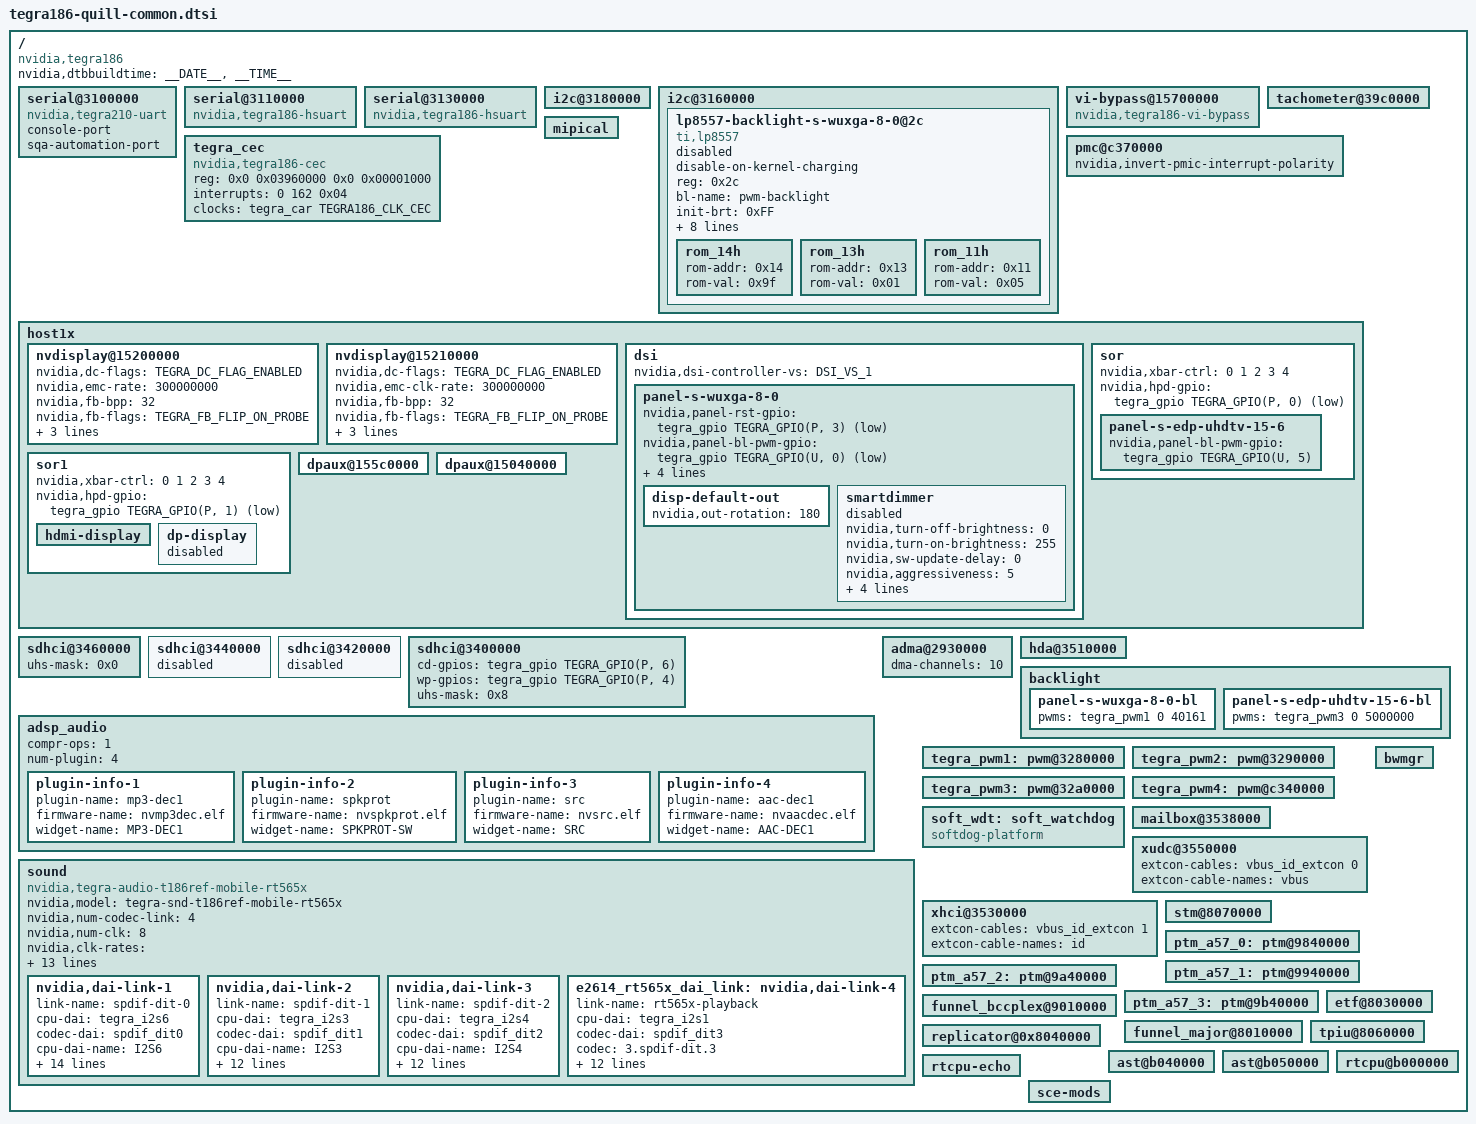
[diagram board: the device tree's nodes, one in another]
/*
 * tegra186-quill-common.dtsi: Quill common dtsi.
 *
 * Copyright (c) 2015-2016, NVIDIA CORPORATION.  All rights reserved.
 *
 * This program is free software; you can redistribute it and/or modify
 * it under the terms of the GNU General Public License as published by
 * the Free Software Foundation; version 2 of the License.
 *
 * This program is distributed in the hope that it will be useful, but WITHOUT
 * ANY WARRANTY; without even the implied warranty of MERCHANTABILITY or
 * FITNESS FOR A PARTICULAR PURPOSE.  See the GNU General Public License for
 * more details.
 */

#include <dt-bindings/types.h>
#include <dt-bindings/gpio/tegra-gpio.h>
/dts-v1/;

/memreserve/ 0x80000000 0x00010000;

#include "tegra186-soc/tegra186-soc-cvm.dtsi"
#include "tegra186-platforms-simple-bus.dtsi"
#include "panel-s-wuxga-8-0.dtsi"
#include "tegra186-platforms/tegra186-quill-eqos.dtsi"
#include "tegra186-hdmi.dtsi"
#include "tegra186-dp.dtsi"
#include "panel-s-edp-uhdtv-15-6.dtsi"
#include "tegra186-quill-pwm-fan.dtsi"
#include "tegra186-quill-thermal-fan-est.dtsi"

/ {
        compatible = "nvidia,tegra186";

        nvidia,dtbbuildtime = __DATE__, __TIME__;
        #address-cells = <2>;
        #size-cells = <2>;

	serial@3100000 {
		compatible = "nvidia,tegra210-uart", "nvidia,tegra186-hsuart";
		console-port;
		sqa-automation-port;
		status = "okay";
	};

	serial@3110000 {
		compatible = "nvidia,tegra186-hsuart";
		status = "okay";
	};

	serial@3130000 {
		compatible = "nvidia,tegra186-hsuart";
		dma-names = "tx";
		status = "okay";
	};

	i2c@3180000 {
		status = "okay";
	};

	i2c@3160000 {
		status = "okay";
		lp8557-backlight-s-wuxga-8-0@2c {
			status = "disabled";
			disable-on-kernel-charging;
			compatible = "ti,lp8557";
			reg = <0x2c>;

			bl-name = "pwm-backlight"; /* Match liblights naming expectations */
			init-brt = /bits/ 8 <0xFF>; /* Max brightness */
			dev-ctrl = /bits/ 8 <0x80>; /* PWM, enable standby mode */
			pwm-period = <40161>;

			pwm-names = "lp8557";
			pwms = <&tegra_pwm1 0 40161>;

			bl-measured = < 0 1 2 3 4 5 5 6
					7 8 9 10 11 11 12 13
					14 15 15 16 17 18 19 20
					21 22 22 23 24 25 26 27
					28 29 30 31 31 32 33 34
					35 36 37 37 38 39 40 41
					41 42 43 44 45 46 47 48
					48 49 50 51 52 53 54 54
					55 56 57 58 58 59 60 61
					62 63 64 65 66 67 68 69
					70 71 72 73 74 75 75 76
					77 78 79 80 81 82 83 84
					85 86 87 88 89 90 91 92
					93 94 94 95 96 97 98 99
					100 101 102 104 105 106 107 108
					109 110 111 112 113 114 115 116
					117 118 119 120 121 122 123 125
					126 127 128 129 130 131 132 133
					134 135 136 137 138 139 140 141
					142 143 144 146 147 148 149 150
					151 152 153 154 155 156 157 158
					159 160 161 162 163 164 165 167
					168 169 170 171 172 173 174 175
					176 178 179 180 181 182 183 184
					185 186 187 188 189 190 191 192
					193 194 195 196 197 199 200 201
					202 203 204 205 206 207 208 210
					211 212 213 214 215 216 217 219
					220 221 222 223 225 226 227 228
					229 230 231 233 234 235 236 237
					238 239 240 241 242 244 245 246
					247 248 249 250 251 253 254 255 >;

			bl-curve = < 0 1 1 2 2 3 3 4
					4 5 5 6 7 7 8 8
					9 9 10 10 11 11 12 12
					13 14 14 15 15 16 16 17
					17 18 18 19 20 20 21 21
					22 22 23 23 24 24 25 25
					26 27 27 28 28 29 29 30
					30 31 31 32 33 33 34 34
					35 35 36 36 37 37 38 38
					39 40 40 41 41 42 42 43
					43 44 44 45 46 46 47 47
					48 48 49 49 50 50 51 52
					52 53 53 54 54 55 55 56
					56 57 57 58 59 59 60 60
					61 61 62 62 63 63 64 65
					65 66 66 67 67 68 68 69
					69 70 70 71 72 72 73 73
					74 74 75 75 76 76 77 78
					78 79 79 80 80 81 81 82
					82 83 83 84 85 85 86 86
					87 87 88 88 89 89 90 92
					94 96 97 99 101 103 105 107
					109 110 112 114 116 118 120 122
					123 125 127 129 131 133 134 136
					138 140 142 144 146 147 149 151
					153 155 157 159 160 162 164 166
					168 170 172 173 175 177 179 181
					183 185 186 188 190 192 194 196
					198 199 201 203 205 207 209 211
					212 214 216 218 220 222 223 225
					227 229 231 233 235 236 238 240
					242 244 246 248 249 251 253 255 >;

			/* 5 LED string */
			rom_14h {
				rom-addr = /bits/ 8 <0x14>;
				rom-val = /bits/ 8 <0x9f>;
			};

			/*Boost freq 1MHZ*/
			rom_13h {
				rom-addr = /bits/ 8 <0x13>;
				rom-val = /bits/ 8 <0x01>;
			};

			/*20mA max */
			rom_11h {
				rom-addr = /bits/ 8 <0x11>;
				rom-val = /bits/ 8 <0x05>;
			};
		};
	};

	vi-bypass@15700000{
		compatible = "nvidia,tegra186-vi-bypass";
		status = "okay";
	};

	tachometer@39c0000 {
		status = "okay";
	};

	tegra_cec {
		status = "okay";
		compatible = "nvidia,tegra186-cec";
		reg = <0x0 0x03960000 0x0 0x00001000>;
		interrupts = <0 162 0x04>;
		clocks = <&tegra_car TEGRA186_CLK_CEC>;
		clock-names = "cec";
	};

	pmc@c370000 {
		nvidia,invert-pmic-interrupt-polarity;
	};

        mipical {
                status = "okay";
        };

	host1x {
		nvdisplay@15200000 {
                        status = "okay";
                        nvidia,dc-flags = <TEGRA_DC_FLAG_ENABLED>;
                        nvidia,emc-rate = <300000000>;
                        nvidia,fb-bpp = <32>;
                        nvidia,fb-flags = <TEGRA_FB_FLIP_ON_PROBE>;
			nvidia,fb-win = <0>;
			nvidia,dc-ctrlnum = <0>;
			nvidia,dc-or-node = "/host1x/dsi";
                };

		nvdisplay@15210000 {
			status = "okay";
			nvidia,dc-flags = <TEGRA_DC_FLAG_ENABLED>;
			nvidia,emc-clk-rate = <300000000>;
			nvidia,fb-bpp = <32>; /* bits per pixel */
			nvidia,fb-flags = <TEGRA_FB_FLIP_ON_PROBE>;
			nvidia,fb-win = <3>;
			nvidia,dc-ctrlnum = <1>;
			nvidia,dc-or-node = "/host1x/sor1";
		};

		dsi {	/* dsi@15300000 */
			nvidia,dsi-controller-vs = <DSI_VS_1>;
			status = "okay";
			panel-s-wuxga-8-0 {
				status = "okay";
				nvidia,panel-rst-gpio = <&tegra_gpio TEGRA_GPIO(P, 3) 1>; /* PP3 */
				nvidia,panel-bl-pwm-gpio = <&tegra_gpio TEGRA_GPIO(U, 0) 1>; /* PU0 */
				nvidia,panel-bl-en-gpio = <&tegra_gpio TEGRA_GPIO(U, 3) 1>; /* PU3 */
				nvidia,panel-en-gpio = <&gpio_i2c_0_77 4 1>; /* tca9539 0x77 Pin 4 */
				nvidia,en-vmm-vpp-with-i2c-config;
				disp-default-out {
					nvidia,out-rotation = <180>;
				};
				smartdimmer {
					status = "disabled";
					nvidia,turn-off-brightness = <0>;
					nvidia,turn-on-brightness = <255>;
					nvidia,sw-update-delay = <0>;
					nvidia,aggressiveness = <5>;
					nvidia,phase-in-settings = <0>;
					nvidia,phase-in-adjustments = <0>;
					nvidia,sd-window-enable = <0>;
					nvidia,bl-device-name = "pwm-backlight";
				};
			};
		};

		sor{
			status = "okay";
			nvidia,xbar-ctrl = <0 1 2 3 4>;
			nvidia,hpd-gpio = <&tegra_gpio TEGRA_GPIO(P, 0) GPIO_ACTIVE_LOW>;
			panel-s-edp-uhdtv-15-6 {
				nvidia,panel-bl-pwm-gpio = <&tegra_gpio TEGRA_GPIO(U, 5) 0>;
			};
		};
		sor1 {
			status = "okay";
			nvidia,xbar-ctrl = <0 1 2 3 4>;
			nvidia,hpd-gpio = <&tegra_gpio TEGRA_GPIO(P, 1) GPIO_ACTIVE_LOW>;
			hdmi-display {
				status = "okay";
			};

			dp-display {
				status = "disabled";
			};
		};
		dpaux@155c0000 {
			status = "okay";
		};
		dpaux@15040000 {
			status = "okay";
		};
	};

	sdhci@3460000 {
		uhs-mask = <0x0>; /*enable HS400 mode*/
		status = "okay";
	};

	sdhci@3440000 {
		status = "disabled";
	};

	sdhci@3420000 {
		status = "disabled";
	};

	sdhci@3400000 {
		cd-gpios = <&tegra_gpio TEGRA_GPIO(P, 6) 0>;
		wp-gpios = <&tegra_gpio TEGRA_GPIO(P, 4) 0>;
		uhs-mask = <0x8>;
		status = "okay";
	};

	adsp_audio {
		compr-ops = <1>;
		num-plugin = <4>;
		plugin-info-1 {
			plugin-name = "mp3-dec1";
			firmware-name = "nvmp3dec.elf";
			widget-name = "MP3-DEC1";
		};
		plugin-info-2 {
			plugin-name = "spkprot";
			firmware-name = "nvspkprot.elf";
			widget-name = "SPKPROT-SW";
		};
		plugin-info-3 {
			plugin-name = "src";
			firmware-name = "nvsrc.elf";
			widget-name = "SRC";
		};
		plugin-info-4 {
			plugin-name = "aac-dec1";
			firmware-name = "nvaacdec.elf";
			widget-name = "AAC-DEC1";
		};
	};

	adma@2930000 {
		dma-channels = <10>;
	};

	hda@3510000 {
		status = "okay";
       };

	sound {
		compatible = "nvidia,tegra-audio-t186ref-mobile-rt565x";
		nvidia,model = "tegra-snd-t186ref-mobile-rt565x";
		nvidia,num-codec-link = <4>;
		nvidia,num-clk = <8>;
		nvidia,clk-rates = < 282240000	/* PLLA_x11025_RATE */
				     11289600	/* AUD_MCLK_x11025_RATE */
				     45158400	/* PLLA_OUT0_x11025_RATE */
				     45158400	/* AHUB_x11025_RATE */
				     368640000  /* PLLA_x8000_RATE */
				     12288000	/* AUD_MCLK_x8000_RATE */
				     36864000	/* PLLA_OUT0_x8000_RATE */
				     36864000 >;/* AHUB_x8000_RATE */
		clocks = <&tegra_car TEGRA186_CLK_PLLP_OUT0>,
			<&tegra_car TEGRA186_CLK_PLLA>,
			<&tegra_car TEGRA186_CLK_PLL_A_OUT0>,
			<&tegra_car TEGRA186_CLK_AHUB>,
			<&tegra_car TEGRA186_CLK_CLK_M>,
			<&tegra_car TEGRA186_CLK_AUD_MCLK>;
		clock-names = "pll_p_out1", "pll_a", "pll_a_out0", "ahub",
				"clk_m", "extern1";
		resets = <&tegra_car TEGRA186_RESET_AUD_MCLK>;
		reset-names = "extern1_rst";

		status = "okay";
		nvidia,audio-routing =
			"y Headphone",		"y OUT",
			"y IN",			"y Mic",
			"z IN",			"z OUT",
			"m Headphone",		"m OUT",
			"m IN",			"m Mic",
			"x Headphone",		"x OUT",
			"x IN",			"x Mic";

		nvidia,xbar = <&tegra_axbar>;

		nvidia,dai-link-1 {
			link-name = "spdif-dit-0";
			cpu-dai = <&tegra_i2s6>;
			codec-dai = <&spdif_dit0>;
			cpu-dai-name = "I2S6";
			codec-dai-name = "dit-hifi";
			tx-mask = <0xFF>;
			rx-mask = <0xFF>;
			format = "dsp_a";
			bitclock-slave;
			frame-slave;
			bitclock-inversion;
			frame-inversion;
			bit-format = "s16_le";
			bclk_ratio = <4>;
			srate = <8000>;
			num-channel = <1>;
			codec = "0.spdif-dit.0";
			name-prefix = "y";
		};
		nvidia,dai-link-2 {
			link-name = "spdif-dit-1";
			cpu-dai = <&tegra_i2s3>;
			codec-dai = <&spdif_dit1>;
			cpu-dai-name = "I2S3";
			codec-dai-name = "dit-hifi";
			format = "i2s";
			bitclock-slave;
			frame-slave;
			bitclock-noninversion;
			frame-noninversion;
			bit-format = "s16_le";
			bclk_ratio = <1>;
			srate = <48000>;
			num-channel = <2>;
			codec = "1.spdif-dit.1";
			name-prefix = "z";
		};
		nvidia,dai-link-3 {
			link-name = "spdif-dit-2";
			cpu-dai = <&tegra_i2s4>;
			codec-dai = <&spdif_dit2>;
			cpu-dai-name = "I2S4";
			codec-dai-name = "dit-hifi";
			format = "i2s";
			bitclock-slave;
			frame-slave;
			bitclock-noninversion;
			frame-noninversion;
			bit-format = "s16_le";
			bclk_ratio = <1>;
			srate = <48000>;
			num-channel = <2>;
			codec = "2.spdif-dit.2";
			name-prefix = "m";
		};
		e2614_rt565x_dai_link: nvidia,dai-link-4 {
			link-name = "rt565x-playback";
			cpu-dai = <&tegra_i2s1>;
			codec-dai = <&spdif_dit3>;
			codec = "3.spdif-dit.3";
			cpu-dai-name = "I2S1";
			codec-dai-name = "dit-hifi";
			format = "i2s";
			bitclock-slave;
			frame-slave;
			bitclock-noninversion;
			frame-noninversion;
			bit-format = "s16_le";
			bclk_ratio = <0>;
			srate = <48000>;
			num-channel = <2>;
			name-prefix = "x";
		};
	};

	backlight {
		status = "okay";
		panel-s-wuxga-8-0-bl {
			pwms = <&tegra_pwm1 0 40161>;
		};
                panel-s-edp-uhdtv-15-6-bl {
                        pwms = <&tegra_pwm3 0 5000000>;
                };
	};

	tegra_pwm1: pwm@3280000 {
		status = "okay";
	};

	tegra_pwm2: pwm@3290000 {
		status = "okay";
	};

	tegra_pwm3: pwm@32a0000 {
		status = "okay";
	};

	tegra_pwm4: pwm@c340000 {
		status = "okay";
	};

	soft_wdt:soft_watchdog {
		compatible = "softdog-platform";
		status = "okay";
	};

	mailbox@3538000 {
		status = "okay";
	};

	xudc@3550000 {
		extcon-cables = <&vbus_id_extcon 0>;
		extcon-cable-names = "vbus";
		#extcon-cells = <1>;
	};

	xhci@3530000 {
		extcon-cables = <&vbus_id_extcon 1>;
		extcon-cable-names = "id";
		#extcon-cells = <1>;
	};

	bwmgr {
		status = "okay";
	};

	stm@8070000 {
		status = "okay";
	};

	ptm_a57_0: ptm@9840000 {
		status = "okay";
	};

	ptm_a57_1: ptm@9940000 {
		status = "okay";
	};

	ptm_a57_2: ptm@9a40000 {
		status = "okay";
	};

	ptm_a57_3: ptm@9b40000 {
		status = "okay";
	};

	funnel_bccplex@9010000 {
		status = "okay";
	};

	funnel_major@8010000 {
		status = "okay";
	};

	replicator@0x8040000 {
		status = "okay";
	};

	etf@8030000 {
		status = "okay";
	};

	tpiu@8060000 {
		status = "okay";
	};

	ast@b040000 {
		status = "okay";
	};

	ast@b050000 {
		status = "okay";
	};

	rtcpu@b000000 {
		status = "okay";
	};

	rtcpu-echo {
		status = "okay";
	};

	sce-mods {
		status = "okay";
	};
};
